# AVR32DA48 device description
Architecture: AVR8X; Family: AVR DA
Registers are 8-bit, read-write, reset 0x0 unless marked. A register's access mark holds for its fields unless they carry their own. Offsets are from the block's base; [hi:lo] are bit positions; lines under a group give offsets from that group; {n}, {i} and the like mark numbered series; 'fields as' and 'values as' point back to an identical list.

## TCA — 16-bit Timer/Counter Type A
Instances: TCA0 0x0A00, TCA1 0x0A40
0x00 SINGLE group (when TCA.SINGLE.CTRLD.SPLITM=0) — 16-bit Timer/Counter Type A - Single Mode
  0x00 CTRLA — Control A
    [7] RUNSTDBY — Run in Standby
    [3:1] CLKSEL — Clock Selection
      0=DIV1 (System Clock); 1=DIV2 (System Clock / 2); 2=DIV4 (System Clock / 4); 3=DIV8 (System Clock / 8); 4=DIV16 (System Clock / 16); 5=DIV64 (System Clock / 64); 6=DIV256 (System Clock / 256); 7=DIV1024 (System Clock / 1024)
    [0] ENABLE — Module Enable
  0x01 CTRLB — Control B
    [6] CMP2EN — Compare 2 Enable
    [5] CMP1EN — Compare 1 Enable
    [4] CMP0EN — Compare 0 Enable
    [3] ALUPD — Auto Lock Update
    [2:0] WGMODE — Waveform generation mode
      0=NORMAL (Normal Mode); 1=FRQ (Frequency Generation Mode); 3=SINGLESLOPE (Single Slope PWM); 5=DSTOP (Dual Slope PWM, overflow on TOP); 6=DSBOTH (Dual Slope PWM, overflow on TOP and BOTTOM); 7=DSBOTTOM (Dual Slope PWM, overflow on BOTTOM)
  0x02 CTRLC — Control C
    [2] CMP2OV — Compare 2 Waveform Output Value
    [1] CMP1OV — Compare 1 Waveform Output Value
    [0] CMP0OV — Compare 0 Waveform Output Value
  0x03 CTRLD — Control D
    [0] SPLITM — Split Mode Enable
  0x04 CTRLECLR — Control E Clear
    [3:2] CMD — Command
      0=NONE (No Command); 1=UPDATE (Force Update); 2=RESTART (Force Restart); 3=RESET (Force Hard Reset)
    [1] LUPD — Lock Update
    [0] DIR — Direction
  0x05 CTRLESET — Control E Set
    [3:2] CMD — Command
      values as SINGLE.CTRLECLR.CMD
    [1] LUPD — Lock Update
    [0] DIR — Direction
      0=UP (Count up); 1=DOWN (Count down)
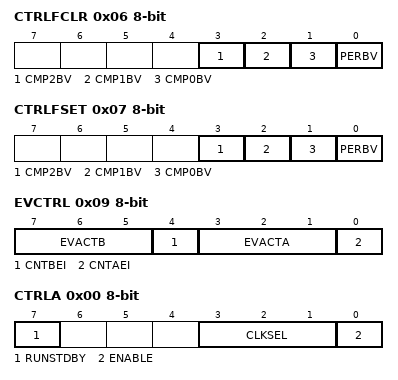
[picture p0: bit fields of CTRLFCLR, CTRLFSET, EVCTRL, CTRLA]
  0x06 CTRLFCLR — Control F Clear
    [3] CMP2BV — Compare 2 Buffer Valid
    [2] CMP1BV — Compare 1 Buffer Valid
    [1] CMP0BV — Compare 0 Buffer Valid
    [0] PERBV — Period Buffer Valid
  0x07 CTRLFSET — Control F Set
    fields as SINGLE.CTRLFCLR
  0x09 EVCTRL — Event Control
    [7:5] EVACTB — Event Action B
      0=NONE (No Action); 3=UPDOWN (Count on prescaled clock. Event controls count direction. Up-count when event line is 0, down-count when event line is 1.); 4=RESTART_POSEDGE (Restart counter at positive edge event); 5=RESTART_ANYEDGE (Restart counter on any edge event); 6=RESTART_HIGHLVL (Restart counter while event line is 1.)
    [4] CNTBEI — Count on Event Input B
    [3:1] EVACTA — Event Action A
      0=CNT_POSEDGE (Count on positive edge event); 1=CNT_ANYEDGE (Count on any edge event); 2=CNT_HIGHLVL (Count on prescaled clock while event line is 1.); 3=UPDOWN (Count on prescaled clock. Event controls count direction. Up-count when event line is 0, down-count when event line is 1.)
    [0] CNTAEI — Count on Event Input A
  0x0A INTCTRL — Interrupt Control
    [6] CMP2 — Compare 2 Interrupt
    [5] CMP1 — Compare 1 Interrupt
    [4] CMP0 — Compare 0 Interrupt
    [0] OVF — Overflow Interrupt
  0x0B INTFLAGS — Interrupt Flags
    fields as SINGLE.INTCTRL
  0x0E DBGCTRL — Degbug Control
    [0] DBGRUN — Debug Run
  0x0F TEMP reset not defined — Temporary data for 16-bit Access
  0x20 CNT 16-bit reset not defined — Count
  0x26 PER 16-bit reset not defined — Period
  {0x28+2j} CMP{j} 16-bit reset not defined (j=0..2) — Compare {j}
  0x36 PERBUF 16-bit reset not defined — Period Buffer
  {0x38+2j} CMP{j}BUF 16-bit reset not defined (j=0..2) — Compare {j} Buffer
0x00 SPLIT group (when TCA.SINGLE.CTRLD.SPLITM=1) — 16-bit Timer/Counter Type A - Split Mode
  0x00 CTRLA — Control A
    fields as SINGLE.CTRLA
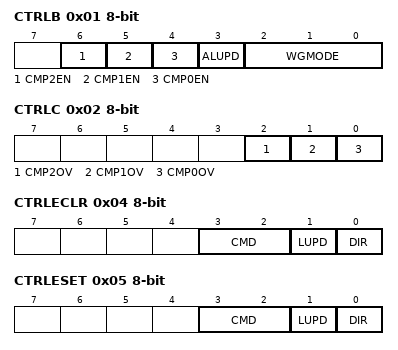
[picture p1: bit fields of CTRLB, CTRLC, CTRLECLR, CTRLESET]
  0x01 CTRLB — Control B
    [6] HCMP2EN — High Compare 2 Enable
    [5] HCMP1EN — High Compare 1 Enable
    [4] HCMP0EN — High Compare 0 Enable
    [2] LCMP2EN — Low Compare 2 Enable
    [1] LCMP1EN — Low Compare 1 Enable
    [0] LCMP0EN — Low Compare 0 Enable
  0x02 CTRLC — Control C
    [6] HCMP2OV — High Compare 2 Output Value
    [5] HCMP1OV — High Compare 1 Output Value
    [4] HCMP0OV — High Compare 0 Output Value
    [2] LCMP2OV — Low Compare 2 Output Value
    [1] LCMP1OV — Low Compare 1 Output Value
    [0] LCMP0OV — Low Compare 0 Output Value
  0x03 CTRLD — Control D
    [0] SPLITM — Split Mode Enable
  0x04 CTRLECLR — Control E Clear
    [3:2] CMD — Command
      values as SINGLE.CTRLECLR.CMD
    [1:0] CMDEN — Command Enable
      0=NONE; 3=BOTH (Both low byte and high byte counter)
  0x05 CTRLESET — Control E Set
    fields as SPLIT.CTRLECLR
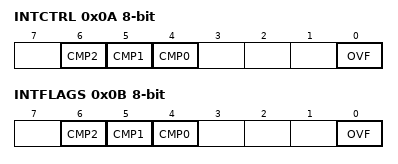
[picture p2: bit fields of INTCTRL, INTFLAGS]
  0x0A INTCTRL — Interrupt Control
    [6] LCMP2 — Low Compare 2 Interrupt Enable
    [5] LCMP1 — Low Compare 1 Interrupt Enable
    [4] LCMP0 — Low Compare 0 Interrupt Enable
    [1] HUNF — High Underflow Interrupt Enable
    [0] LUNF — Low Underflow Interrupt Enable
  0x0B INTFLAGS — Interrupt Flags
    [6] LCMP2 — Low Compare 0 Interrupt Flag
    [5] LCMP1 — Low Compare 1 Interrupt Flag
    [4] LCMP0 — Low Compare 2 Interrupt Flag
    [1] HUNF — High Underflow Interrupt Flag
    [0] LUNF — Low Underflow Interrupt Flag
  0x0E DBGCTRL — Degbug Control
    [0] DBGRUN — Debug Run
  0x20 LCNT reset not defined — Low Count
  0x21 HCNT reset not defined — High Count
  0x26 LPER reset not defined — Low Period
  0x27 HPER reset not defined — High Period
  {0x28+2j} LCMP{j} reset not defined (j=0..2) — Low Compare
  {0x29+2j} HCMP{j} reset not defined (j=0..2) — High Compare
